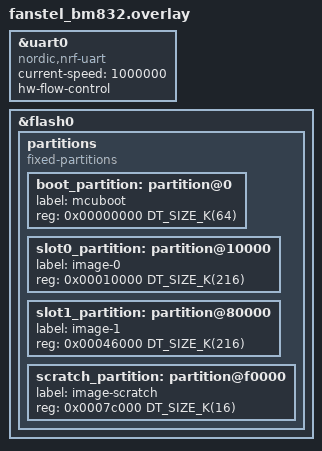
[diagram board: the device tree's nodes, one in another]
/* SPDX-License-Identifier: Apache-2.0 */

&uart0 {
	compatible = "nordic,nrf-uart";
	current-speed = <1000000>;
	status = "okay";
	hw-flow-control;
};

&flash0 {

	partitions {
		compatible = "fixed-partitions";
		#address-cells = <1>;
		#size-cells = <1>;

		boot_partition: partition@0 {
			label = "mcuboot";
			reg = <0x00000000 DT_SIZE_K(64)>;
		};
		slot0_partition: partition@10000 {
			label = "image-0";
			reg = <0x00010000 DT_SIZE_K(216)>;
		};
		slot1_partition: partition@80000 {
			label = "image-1";
			reg = <0x00046000 DT_SIZE_K(216)>;
		};
		scratch_partition: partition@f0000 {
			label = "image-scratch";
			reg = <0x0007c000 DT_SIZE_K(16)>;
		};
	};
};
